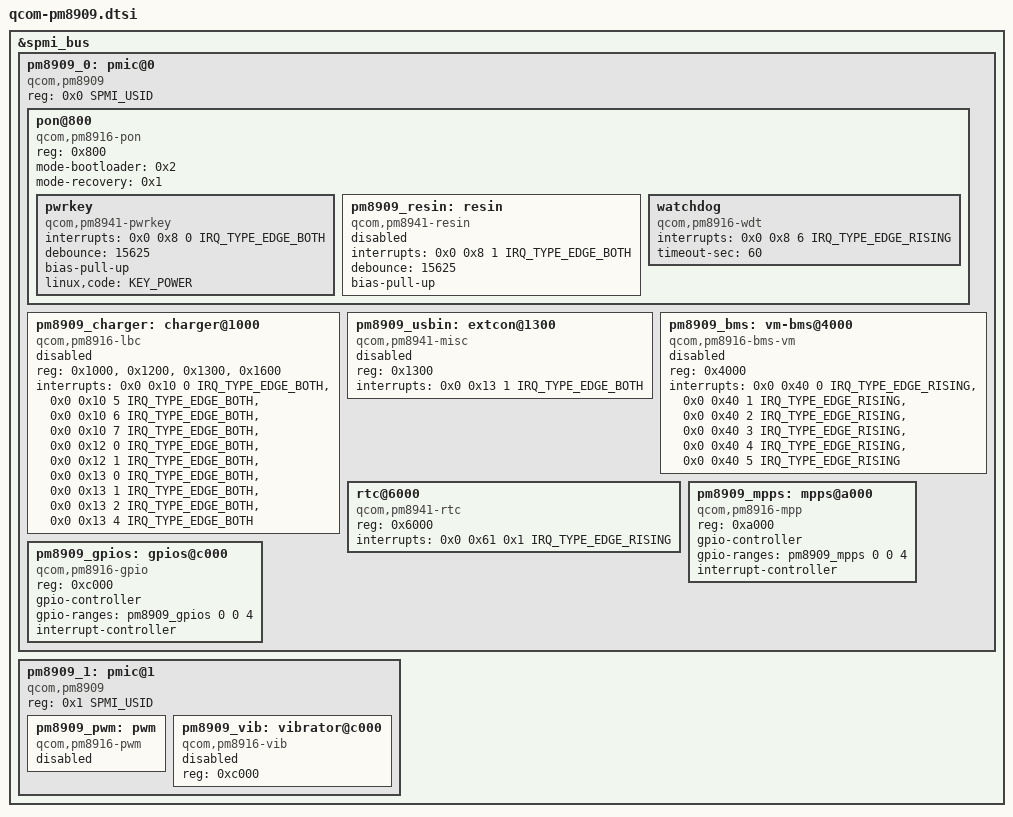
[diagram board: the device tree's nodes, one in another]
// SPDX-License-Identifier: GPL-2.0-only
#include <dt-bindings/input/linux-event-codes.h>
#include <dt-bindings/interrupt-controller/irq.h>
#include <dt-bindings/spmi/spmi.h>

&spmi_bus {
	pm8909_0: pmic@0 {
		compatible = "qcom,pm8909", "qcom,spmi-pmic";
		reg = <0x0 SPMI_USID>;
		#address-cells = <1>;
		#size-cells = <0>;

		pon@800 {
			compatible = "qcom,pm8916-pon";
			reg = <0x800>;
			mode-bootloader = <0x2>;
			mode-recovery = <0x1>;

			pwrkey {
				compatible = "qcom,pm8941-pwrkey";
				interrupts = <0x0 0x8 0 IRQ_TYPE_EDGE_BOTH>;
				debounce = <15625>;
				bias-pull-up;
				linux,code = <KEY_POWER>;
			};

			pm8909_resin: resin {
				compatible = "qcom,pm8941-resin";
				interrupts = <0x0 0x8 1 IRQ_TYPE_EDGE_BOTH>;
				debounce = <15625>;
				bias-pull-up;
				status = "disabled";
			};

			watchdog {
				compatible = "qcom,pm8916-wdt";
				interrupts = <0x0 0x8 6 IRQ_TYPE_EDGE_RISING>;
				timeout-sec = <60>;
			};
		};

		pm8909_charger: charger@1000 {
			compatible = "qcom,pm8916-lbc";
			reg = <0x1000>, <0x1200>, <0x1300>, <0x1600>;
			reg-names = "chgr", "bat_if", "usb", "misc";

			interrupts = <0x0 0x10 0 IRQ_TYPE_EDGE_BOTH>,
				     <0x0 0x10 5 IRQ_TYPE_EDGE_BOTH>,
				     <0x0 0x10 6 IRQ_TYPE_EDGE_BOTH>,
				     <0x0 0x10 7 IRQ_TYPE_EDGE_BOTH>,
				     <0x0 0x12 0 IRQ_TYPE_EDGE_BOTH>,
				     <0x0 0x12 1 IRQ_TYPE_EDGE_BOTH>,
				     <0x0 0x13 0 IRQ_TYPE_EDGE_BOTH>,
				     <0x0 0x13 1 IRQ_TYPE_EDGE_BOTH>,
				     <0x0 0x13 2 IRQ_TYPE_EDGE_BOTH>,
				     <0x0 0x13 4 IRQ_TYPE_EDGE_BOTH>;
			interrupt-names = "vbat_det",
					  "fast_chg",
					  "chg_fail",
					  "chg_done",
					  "bat_pres",
					  "temp_ok",
					  "coarse_det",
					  "usb_vbus",
					  "chg_gone",
					  "overtemp";

			status = "disabled";
		};

		pm8909_usbin: extcon@1300 {
			compatible = "qcom,pm8941-misc";
			reg = <0x1300>;
			interrupts = <0x0 0x13 1 IRQ_TYPE_EDGE_BOTH>;
			interrupt-names = "usb_vbus";
			status = "disabled";
		};

		pm8909_bms: vm-bms@4000 {
			compatible = "qcom,pm8916-bms-vm";
			reg = <0x4000>;

			interrupts = <0x0 0x40 0 IRQ_TYPE_EDGE_RISING>,
				     <0x0 0x40 1 IRQ_TYPE_EDGE_RISING>,
				     <0x0 0x40 2 IRQ_TYPE_EDGE_RISING>,
				     <0x0 0x40 3 IRQ_TYPE_EDGE_RISING>,
				     <0x0 0x40 4 IRQ_TYPE_EDGE_RISING>,
				     <0x0 0x40 5 IRQ_TYPE_EDGE_RISING>;
			interrupt-names = "cv_leave",
					  "cv_enter",
					  "ocv_good",
					  "ocv_thr",
					  "fifo",
					  "state_chg";

			status = "disabled";
		};

		rtc@6000 {
			compatible = "qcom,pm8941-rtc";
			reg = <0x6000>;
			interrupts = <0x0 0x61 0x1 IRQ_TYPE_EDGE_RISING>;
		};

		pm8909_mpps: mpps@a000 {
			compatible = "qcom,pm8916-mpp", "qcom,spmi-mpp";
			reg = <0xa000>;
			gpio-controller;
			#gpio-cells = <2>;
			gpio-ranges = <&pm8909_mpps 0 0 4>;
			interrupt-controller;
			#interrupt-cells = <2>;
		};

		pm8909_gpios: gpios@c000 {
			compatible = "qcom,pm8916-gpio", "qcom,spmi-gpio";
			reg = <0xc000>;
			gpio-controller;
			gpio-ranges = <&pm8909_gpios 0 0 4>;
			#gpio-cells = <2>;
			interrupt-controller;
			#interrupt-cells = <2>;
		};
	};

	pm8909_1: pmic@1 {
		compatible = "qcom,pm8909", "qcom,spmi-pmic";
		reg = <0x1 SPMI_USID>;
		#address-cells = <1>;
		#size-cells = <0>;

		pm8909_pwm: pwm {
			compatible = "qcom,pm8916-pwm";

			#pwm-cells = <2>;

			status = "disabled";
		};

		pm8909_vib: vibrator@c000 {
			compatible = "qcom,pm8916-vib";
			reg = <0xc000>;
			status = "disabled";
		};
	};
};
